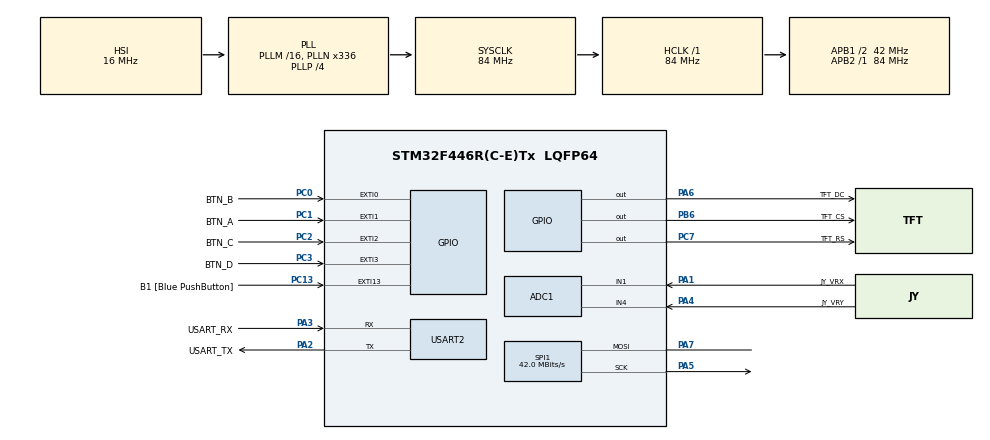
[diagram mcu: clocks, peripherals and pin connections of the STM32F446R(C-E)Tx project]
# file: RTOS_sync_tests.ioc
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ADC1.Channel-0\#ChannelRegularConversion=ADC_CHANNEL_1
ADC1.Channel-1\#ChannelRegularConversion=ADC_CHANNEL_4
ADC1.ContinuousConvMode=ENABLE
ADC1.DMAContinuousRequests=ENABLE
ADC1.DiscontinuousConvMode=DISABLE
ADC1.NbrOfConversion=2
ADC1.NbrOfConversionFlag=1
ADC1.Rank-0\#ChannelRegularConversion=1
ADC1.Rank-1\#ChannelRegularConversion=2
ADC1.SamplingTime-0\#ChannelRegularConversion=ADC_SAMPLETIME_112CYCLES
ADC1.SamplingTime-1\#ChannelRegularConversion=ADC_SAMPLETIME_112CYCLES
ADC1.ScanConvMode=ENABLE
ADC1.master=1
Dma.ADC1.1.Direction=DMA_PERIPH_TO_MEMORY
Dma.ADC1.1.FIFOMode=DMA_FIFOMODE_DISABLE
Dma.ADC1.1.Instance=DMA2_Stream0
Dma.ADC1.1.MemDataAlignment=DMA_MDATAALIGN_HALFWORD
Dma.ADC1.1.MemInc=DMA_MINC_ENABLE
Dma.ADC1.1.Mode=DMA_CIRCULAR
Dma.ADC1.1.PeriphDataAlignment=DMA_PDATAALIGN_HALFWORD
Dma.ADC1.1.PeriphInc=DMA_PINC_DISABLE
Dma.ADC1.1.Priority=DMA_PRIORITY_HIGH
Dma.Request0=SPI1_TX
Dma.Request1=ADC1
Dma.Request2=USART2_TX
Dma.Request3=USART2_RX
Dma.SPI1_TX.0.Direction=DMA_MEMORY_TO_PERIPH
Dma.SPI1_TX.0.FIFOMode=DMA_FIFOMODE_DISABLE
Dma.SPI1_TX.0.Instance=DMA2_Stream3
Dma.SPI1_TX.0.MemDataAlignment=DMA_MDATAALIGN_BYTE
Dma.SPI1_TX.0.MemInc=DMA_MINC_ENABLE
Dma.SPI1_TX.0.Mode=DMA_NORMAL
Dma.SPI1_TX.0.PeriphDataAlignment=DMA_PDATAALIGN_BYTE
Dma.SPI1_TX.0.PeriphInc=DMA_PINC_DISABLE
Dma.SPI1_TX.0.Priority=DMA_PRIORITY_HIGH
Dma.USART2_RX.3.Direction=DMA_PERIPH_TO_MEMORY
Dma.USART2_RX.3.FIFOMode=DMA_FIFOMODE_DISABLE
Dma.USART2_RX.3.Instance=DMA1_Stream5
Dma.USART2_RX.3.MemDataAlignment=DMA_MDATAALIGN_BYTE
Dma.USART2_RX.3.MemInc=DMA_MINC_ENABLE
Dma.USART2_RX.3.Mode=DMA_CIRCULAR
Dma.USART2_RX.3.PeriphDataAlignment=DMA_PDATAALIGN_BYTE
Dma.USART2_RX.3.PeriphInc=DMA_PINC_DISABLE
Dma.USART2_RX.3.Priority=DMA_PRIORITY_LOW
Dma.USART2_TX.2.Direction=DMA_MEMORY_TO_PERIPH
Dma.USART2_TX.2.FIFOMode=DMA_FIFOMODE_DISABLE
Dma.USART2_TX.2.Instance=DMA1_Stream6
Dma.USART2_TX.2.MemDataAlignment=DMA_MDATAALIGN_BYTE
Dma.USART2_TX.2.MemInc=DMA_MINC_ENABLE
Dma.USART2_TX.2.Mode=DMA_NORMAL
Dma.USART2_TX.2.PeriphDataAlignment=DMA_PDATAALIGN_BYTE
Dma.USART2_TX.2.PeriphInc=DMA_PINC_DISABLE
Dma.USART2_TX.2.Priority=DMA_PRIORITY_MEDIUM
FREERTOS.Tasks01=defaultTask,0,128,StartDefaultTask,Default,NULL,Dynamic,NULL,NULL
FREERTOS.configTIMER_TASK_PRIORITY=6
FREERTOS.configUSE_TIMERS=1
Mcu.Family=STM32F4
Mcu.Name=STM32F446R(C-E)Tx
Mcu.Package=LQFP64
NVIC.DMA1_Stream5_IRQn=true\:5\:0\:false\:false\:true\:true\:false\:true\:true
NVIC.DMA1_Stream6_IRQn=true\:5\:0\:false\:false\:true\:true\:false\:true\:true
NVIC.DMA2_Stream0_IRQn=true\:5\:0\:false\:false\:true\:true\:false\:true\:true
NVIC.DMA2_Stream3_IRQn=true\:5\:0\:false\:false\:true\:true\:false\:true\:true
NVIC.EXTI0_IRQn=true\:5\:0\:false\:false\:true\:true\:true\:true\:true
NVIC.EXTI1_IRQn=true\:5\:0\:false\:false\:true\:true\:true\:true\:true
NVIC.EXTI2_IRQn=true\:5\:0\:false\:false\:true\:true\:true\:true\:true
NVIC.EXTI3_IRQn=true\:5\:0\:false\:false\:true\:true\:true\:true\:true
NVIC.PriorityGroup=NVIC_PRIORITYGROUP_4
NVIC.TIM5_IRQn=true\:15\:0\:false\:false\:true\:false\:false\:true\:true
NVIC.TimeBase=TIM5_IRQn
NVIC.TimeBaseIP=TIM5
NVIC.USART2_IRQn=true\:5\:0\:false\:false\:true\:true\:true\:true\:true
PA1.GPIO_Label=JY_VRX
PA1.Signal=ADCx_IN1
PA13.GPIO_Label=TMS
PA13.Mode=Serial_Wire
PA13.Signal=SYS_JTMS-SWDIO
PA14.GPIO_Label=TCK
PA14.Mode=Serial_Wire
PA14.Signal=SYS_JTCK-SWCLK
PA2.GPIO_Label=USART_TX
PA2.Mode=Asynchronous
PA2.Signal=USART2_TX
PA3.GPIO_Label=USART_RX
PA3.Mode=Asynchronous
PA3.Signal=USART2_RX
PA4.GPIO_Label=JY_VRY
PA4.Signal=ADCx_IN4
PA5.Mode=Simplex_Bidirectional_Master
PA5.Signal=SPI1_SCK
PA6.GPIO_Label=TFT_DC
PA6.Signal=GPIO_Output
PA7.Mode=Simplex_Bidirectional_Master
PA7.Signal=SPI1_MOSI
PB3.GPIO_Label=SWO
PB3.Signal=SYS_JTDO-SWO
PB6.GPIO_Label=TFT_CS
PB6.PinState=GPIO_PIN_SET
PB6.Signal=GPIO_Output
PC0.GPIO_Label=BTN_B
PC0.GPIO_ModeDefaultEXTI=GPIO_MODE_IT_FALLING
PC0.GPIO_PuPd=GPIO_PULLUP
PC0.Signal=GPXTI0
PC1.GPIO_Label=BTN_A
PC1.GPIO_ModeDefaultEXTI=GPIO_MODE_IT_FALLING
PC1.GPIO_PuPd=GPIO_PULLUP
PC1.Signal=GPXTI1
PC13.GPIO_Label=B1 [Blue PushButton]
PC13.GPIO_ModeDefaultEXTI=GPIO_MODE_IT_FALLING
PC13.Signal=GPXTI13
PC14-OSC32_IN.Mode=LSE-External-Oscillator
PC14-OSC32_IN.Signal=RCC_OSC32_IN
PC15-OSC32_OUT.Mode=LSE-External-Oscillator
PC15-OSC32_OUT.Signal=RCC_OSC32_OUT
PC2.GPIO_Label=BTN_C
PC2.GPIO_ModeDefaultEXTI=GPIO_MODE_IT_FALLING
PC2.GPIO_PuPd=GPIO_PULLUP
PC2.Signal=GPXTI2
PC3.GPIO_Label=BTN_D
PC3.GPIO_ModeDefaultEXTI=GPIO_MODE_IT_FALLING
PC3.GPIO_PuPd=GPIO_PULLUP
PC3.Signal=GPXTI3
PC7.GPIO_Label=TFT_RS
PC7.PinState=GPIO_PIN_SET
PC7.Signal=GPIO_Output
PH0-OSC_IN.Mode=HSE-External-Oscillator
PH0-OSC_IN.Signal=RCC_OSC_IN
PH1-OSC_OUT.Mode=HSE-External-Oscillator
PH1-OSC_OUT.Signal=RCC_OSC_OUT
ProjectManager.HeapSize=0x200
ProjectManager.StackSize=0x400
ProjectManager.TargetToolchain=STM32CubeIDE
RCC.48MHZClocksFreq_Value=84000000
RCC.AHBFreq_Value=84000000
RCC.APB1CLKDivider=RCC_HCLK_DIV2
RCC.APB1Freq_Value=42000000
RCC.APB1TimFreq_Value=84000000
RCC.APB2Freq_Value=84000000
RCC.APB2TimFreq_Value=84000000
RCC.CortexFreq_Value=84000000
RCC.FLatency-AdvancedSettings=FLASH_LATENCY_2
RCC.HCLKFreq_Value=84000000
RCC.HSE_VALUE=8000000
RCC.HSI_VALUE=16000000
RCC.PLLN=336
RCC.PLLP=RCC_PLLP_DIV4
RCC.SYSCLKFreq_VALUE=84000000
RCC.SYSCLKSource=RCC_SYSCLKSOURCE_PLLCLK
RCC.USBFreq_Value=168000000
RCC.VCOOutputFreq_Value=336000000
SH.ADCx_IN1.0=ADC1_IN1,IN1
SH.ADCx_IN4.0=ADC1_IN4,IN4
SPI1.CalculateBaudRate=42.0 MBits/s
SPI1.Direction=SPI_DIRECTION_1LINE
SPI1.Mode=SPI_MODE_MASTER
SPI1.VirtualType=VM_MASTER
USART2.VirtualMode=VM_ASYNC
VP_FREERTOS_VS_CMSIS_V1.Mode=CMSIS_V1
VP_SYS_VS_tim5.Mode=TIM5
board=NUCLEO-F446RE

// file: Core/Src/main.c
/* USER CODE BEGIN Header */
/**
  ******************************************************************************
  * @file           : main.c
  * @brief          : Main program body
  ******************************************************************************
  * @attention
  *
  * Copyright (c) 2025 STMicroelectronics.
  * All rights reserved.
  *
  * This software is licensed under terms that can be found in the LICENSE file
  * in the root directory of this software component.
  * If no LICENSE file comes with this software, it is provided AS-IS.
  *
  ******************************************************************************
  */
/* USER CODE END Header */
#include "main.h"
#include "cmsis_os.h"

/* USER CODE BEGIN Includes */
#include "BootMng.h"
/* USER CODE END Includes */

ADC_HandleTypeDef hadc1;
DMA_HandleTypeDef hdma_adc1;

SPI_HandleTypeDef hspi1;
DMA_HandleTypeDef hdma_spi1_tx;

extern UART_HandleTypeDef huart2;
extern DMA_HandleTypeDef hdma_usart2_tx;
extern DMA_HandleTypeDef hdma_usart2_rx;

osThreadId defaultTaskHandle;

void SystemClock_Config(void);
static void MX_GPIO_Init(void);
static void MX_DMA_Init(void);
static void MX_USART2_UART_Init(void);
static void MX_SPI1_Init(void);
static void MX_ADC1_Init(void);
void StartDefaultTask(void const * argument);

int main(void)
{

  /* USER CODE BEGIN 1 */
// initialise_monitor_handles();
  /* USER CODE END 1 */

  /* MCU Configuration--------------------------------------------------------*/

  /* Reset of all peripherals, Initializes the Flash interface and the Systick. */
  HAL_Init();

  /* Configure the system clock */
  SystemClock_Config();

  /* Initialize all configured peripherals */
  MX_GPIO_Init();
  MX_DMA_Init();
  MX_USART2_UART_Init();
  MX_SPI1_Init();
  MX_ADC1_Init();
  /* USER CODE BEGIN 2 */

  	  bootInit();
      vTaskStartScheduler();

  /* USER CODE END 2 */

  /* Create the thread(s) */
  /* definition and creation of defaultTask */
  osThreadDef(defaultTask, StartDefaultTask, osPriorityNormal, 0, 128);
  defaultTaskHandle = osThreadCreate(osThread(defaultTask), NULL);

  /* Start scheduler */
  osKernelStart();

  /* We should never get here as control is now taken by the scheduler */

  /* Infinite loop */
  while (1)
  {

  }
}

void SystemClock_Config(void)
{
  RCC_OscInitTypeDef RCC_OscInitStruct = {0};
  RCC_ClkInitTypeDef RCC_ClkInitStruct = {0};

  /** Configure the main internal regulator output voltage
  */
  __HAL_RCC_PWR_CLK_ENABLE();
  __HAL_PWR_VOLTAGESCALING_CONFIG(PWR_REGULATOR_VOLTAGE_SCALE3);

  /** Initializes the RCC Oscillators according to the specified parameters
  * in the RCC_OscInitTypeDef structure.
  */
  RCC_OscInitStruct.OscillatorType = RCC_OSCILLATORTYPE_HSI;
  RCC_OscInitStruct.HSIState = RCC_HSI_ON;
  RCC_OscInitStruct.HSICalibrationValue = RCC_HSICALIBRATION_DEFAULT;
  RCC_OscInitStruct.PLL.PLLState = RCC_PLL_ON;
  RCC_OscInitStruct.PLL.PLLSource = RCC_PLLSOURCE_HSI;
  RCC_OscInitStruct.PLL.PLLM = 16;
  RCC_OscInitStruct.PLL.PLLN = 336;
  RCC_OscInitStruct.PLL.PLLP = RCC_PLLP_DIV4;
  RCC_OscInitStruct.PLL.PLLQ = 2;
  RCC_OscInitStruct.PLL.PLLR = 2;
  if (HAL_RCC_OscConfig(&RCC_OscInitStruct) != HAL_OK)
  {
    Error_Handler();
  }

  /** Initializes the CPU, AHB and APB buses clocks
  */
  RCC_ClkInitStruct.ClockType = RCC_CLOCKTYPE_HCLK|RCC_CLOCKTYPE_SYSCLK
                              |RCC_CLOCKTYPE_PCLK1|RCC_CLOCKTYPE_PCLK2;
  RCC_ClkInitStruct.SYSCLKSource = RCC_SYSCLKSOURCE_PLLCLK;
  RCC_ClkInitStruct.AHBCLKDivider = RCC_SYSCLK_DIV1;
  RCC_ClkInitStruct.APB1CLKDivider = RCC_HCLK_DIV2;
  RCC_ClkInitStruct.APB2CLKDivider = RCC_HCLK_DIV1;

  if (HAL_RCC_ClockConfig(&RCC_ClkInitStruct, FLASH_LATENCY_2) != HAL_OK)
  {
    Error_Handler();
  }
}

static void MX_ADC1_Init(void)
{

  ADC_ChannelConfTypeDef sConfig = {0};

  /** Configure the global features of the ADC (Clock, Resolution, Data Alignment and number of conversion)
  */
  hadc1.Instance = ADC1;
  hadc1.Init.ClockPrescaler = ADC_CLOCK_SYNC_PCLK_DIV4;
  hadc1.Init.Resolution = ADC_RESOLUTION_12B;
  hadc1.Init.ScanConvMode = ENABLE;
  hadc1.Init.ContinuousConvMode = ENABLE;
  hadc1.Init.DiscontinuousConvMode = DISABLE;
  hadc1.Init.ExternalTrigConvEdge = ADC_EXTERNALTRIGCONVEDGE_NONE;
  hadc1.Init.ExternalTrigConv = ADC_SOFTWARE_START;
  hadc1.Init.DataAlign = ADC_DATAALIGN_RIGHT;
  hadc1.Init.NbrOfConversion = 2;
  hadc1.Init.DMAContinuousRequests = ENABLE;
  hadc1.Init.EOCSelection = ADC_EOC_SINGLE_CONV;
  if (HAL_ADC_Init(&hadc1) != HAL_OK)
  {
    Error_Handler();
  }

  /** Configure for the selected ADC regular channel its corresponding rank in the sequencer and its sample time.
  */
  sConfig.Channel = ADC_CHANNEL_1;
  sConfig.Rank = 1;
  sConfig.SamplingTime = ADC_SAMPLETIME_112CYCLES;
  if (HAL_ADC_ConfigChannel(&hadc1, &sConfig) != HAL_OK)
  {
    Error_Handler();
  }

  /** Configure for the selected ADC regular channel its corresponding rank in the sequencer and its sample time.
  */
  sConfig.Channel = ADC_CHANNEL_4;
  sConfig.Rank = 2;
  if (HAL_ADC_ConfigChannel(&hadc1, &sConfig) != HAL_OK)
  {
    Error_Handler();
  }

}

static void MX_SPI1_Init(void)
{

  /* SPI1 parameter configuration*/
  hspi1.Instance = SPI1;
  hspi1.Init.Mode = SPI_MODE_MASTER;
  hspi1.Init.Direction = SPI_DIRECTION_1LINE;
  hspi1.Init.DataSize = SPI_DATASIZE_8BIT;
  hspi1.Init.CLKPolarity = SPI_POLARITY_LOW;
  hspi1.Init.CLKPhase = SPI_PHASE_1EDGE;
  hspi1.Init.NSS = SPI_NSS_SOFT;
  hspi1.Init.BaudRatePrescaler = SPI_BAUDRATEPRESCALER_2;
  hspi1.Init.FirstBit = SPI_FIRSTBIT_MSB;
  hspi1.Init.TIMode = SPI_TIMODE_DISABLE;
  hspi1.Init.CRCCalculation = SPI_CRCCALCULATION_DISABLE;
  hspi1.Init.CRCPolynomial = 10;
  if (HAL_SPI_Init(&hspi1) != HAL_OK)
  {
    Error_Handler();
  }

}

static void MX_USART2_UART_Init(void)
{

  /* USER CODE BEGIN USART2_Init 0 */
//
  /* USER CODE END USART2_Init 0 */

  /* USER CODE BEGIN USART2_Init 1 */
//
  /* USER CODE END USART2_Init 1 */
  huart2.Instance = USART2;
  huart2.Init.BaudRate = 115200;
  huart2.Init.WordLength = UART_WORDLENGTH_8B;
  huart2.Init.StopBits = UART_STOPBITS_1;
  huart2.Init.Parity = UART_PARITY_NONE;
  huart2.Init.Mode = UART_MODE_TX_RX;
  huart2.Init.HwFlowCtl = UART_HWCONTROL_NONE;
  huart2.Init.OverSampling = UART_OVERSAMPLING_16;
  if (HAL_UART_Init(&huart2) != HAL_OK)
  {
    Error_Handler();
  }
  /* USER CODE BEGIN USART2_Init 2 */
//
  /* USER CODE END USART2_Init 2 */

}

static void MX_DMA_Init(void)
{

  /* DMA controller clock enable */
  __HAL_RCC_DMA2_CLK_ENABLE();
  __HAL_RCC_DMA1_CLK_ENABLE();

  /* DMA interrupt init */
  /* DMA1_Stream5_IRQn interrupt configuration */
  HAL_NVIC_SetPriority(DMA1_Stream5_IRQn, 5, 0);
  HAL_NVIC_EnableIRQ(DMA1_Stream5_IRQn);
  /* DMA1_Stream6_IRQn interrupt configuration */
  HAL_NVIC_SetPriority(DMA1_Stream6_IRQn, 5, 0);
  HAL_NVIC_EnableIRQ(DMA1_Stream6_IRQn);
  /* DMA2_Stream0_IRQn interrupt configuration */
  HAL_NVIC_SetPriority(DMA2_Stream0_IRQn, 5, 0);
  HAL_NVIC_EnableIRQ(DMA2_Stream0_IRQn);
  /* DMA2_Stream3_IRQn interrupt configuration */
  HAL_NVIC_SetPriority(DMA2_Stream3_IRQn, 5, 0);
  HAL_NVIC_EnableIRQ(DMA2_Stream3_IRQn);

}

static void MX_GPIO_Init(void)
{
  GPIO_InitTypeDef GPIO_InitStruct = {0};

  /* GPIO Ports Clock Enable */
  __HAL_RCC_GPIOC_CLK_ENABLE();
  __HAL_RCC_GPIOH_CLK_ENABLE();
  __HAL_RCC_GPIOA_CLK_ENABLE();
  __HAL_RCC_GPIOB_CLK_ENABLE();

  /*Configure GPIO pin Output Level */
  HAL_GPIO_WritePin(TFT_DC_GPIO_Port, TFT_DC_Pin, GPIO_PIN_RESET);

  /*Configure GPIO pin Output Level */
  HAL_GPIO_WritePin(TFT_RS_GPIO_Port, TFT_RS_Pin, GPIO_PIN_SET);

  /*Configure GPIO pin Output Level */
  HAL_GPIO_WritePin(TFT_CS_GPIO_Port, TFT_CS_Pin, GPIO_PIN_SET);

  /*Configure GPIO pin : B1_Pin */
  GPIO_InitStruct.Pin = B1_Pin;
  GPIO_InitStruct.Mode = GPIO_MODE_IT_FALLING;
  GPIO_InitStruct.Pull = GPIO_NOPULL;
  HAL_GPIO_Init(B1_GPIO_Port, &GPIO_InitStruct);

  /*Configure GPIO pins : BTN_B_Pin BTN_A_Pin BTN_C_Pin BTN_D_Pin */
  GPIO_InitStruct.Pin = BTN_B_Pin|BTN_A_Pin|BTN_C_Pin|BTN_D_Pin;
  GPIO_InitStruct.Mode = GPIO_MODE_IT_FALLING;
  GPIO_InitStruct.Pull = GPIO_PULLUP;
  HAL_GPIO_Init(GPIOC, &GPIO_InitStruct);

  /*Configure GPIO pin : TFT_DC_Pin */
  GPIO_InitStruct.Pin = TFT_DC_Pin;
  GPIO_InitStruct.Mode = GPIO_MODE_OUTPUT_PP;
  GPIO_InitStruct.Pull = GPIO_NOPULL;
  GPIO_InitStruct.Speed = GPIO_SPEED_FREQ_LOW;
  HAL_GPIO_Init(TFT_DC_GPIO_Port, &GPIO_InitStruct);

  /*Configure GPIO pin : TFT_RS_Pin */
  GPIO_InitStruct.Pin = TFT_RS_Pin;
  GPIO_InitStruct.Mode = GPIO_MODE_OUTPUT_PP;
  GPIO_InitStruct.Pull = GPIO_NOPULL;
  GPIO_InitStruct.Speed = GPIO_SPEED_FREQ_LOW;
  HAL_GPIO_Init(TFT_RS_GPIO_Port, &GPIO_InitStruct);

  /*Configure GPIO pin : TFT_CS_Pin */
  GPIO_InitStruct.Pin = TFT_CS_Pin;
  GPIO_InitStruct.Mode = GPIO_MODE_OUTPUT_PP;
  GPIO_InitStruct.Pull = GPIO_NOPULL;
  GPIO_InitStruct.Speed = GPIO_SPEED_FREQ_LOW;
  HAL_GPIO_Init(TFT_CS_GPIO_Port, &GPIO_InitStruct);

  /* EXTI interrupt init*/
  HAL_NVIC_SetPriority(EXTI0_IRQn, 5, 0);
  HAL_NVIC_EnableIRQ(EXTI0_IRQn);

  HAL_NVIC_SetPriority(EXTI1_IRQn, 5, 0);
  HAL_NVIC_EnableIRQ(EXTI1_IRQn);

  HAL_NVIC_SetPriority(EXTI2_IRQn, 5, 0);
  HAL_NVIC_EnableIRQ(EXTI2_IRQn);

  HAL_NVIC_SetPriority(EXTI3_IRQn, 5, 0);
  HAL_NVIC_EnableIRQ(EXTI3_IRQn);

}

void StartDefaultTask(void const * argument)
{
  for(;;)
  {
    osDelay(1);
  }
}

void HAL_TIM_PeriodElapsedCallback(TIM_HandleTypeDef *htim)
{
  if (htim->Instance == TIM5)
  {
    HAL_IncTick();
  }
}

void Error_Handler(void)
{
  __disable_irq();
  while (1)
  {
  }
}
